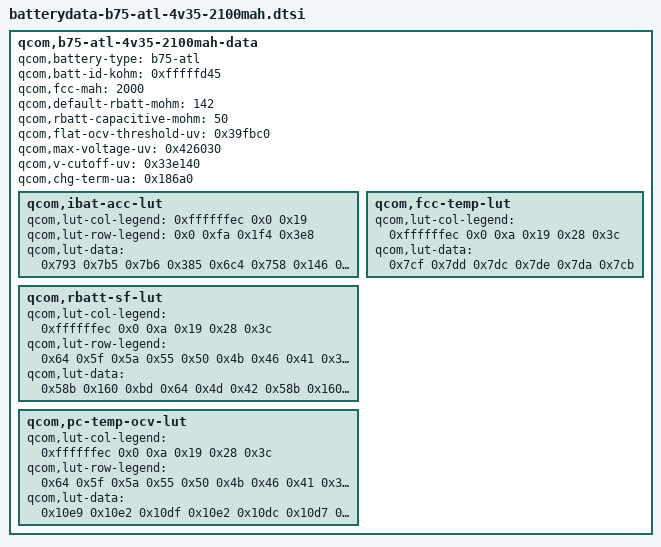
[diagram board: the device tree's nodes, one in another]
/* Copyright (c) 2020, The Linux Foundation. All rights reserved.
*  Copyright (c) 2020, the_shahnawaz_sheikh (sheikhshahnawaz41299).
*
* This program is free software; you can redistribute it and/or modify
* it under the terms of the GNU General Public License version 2 and
* only version 2 as published by the Free Software Foundation.
*
* This program is distributed in the hope that it will be useful,
* but WITHOUT ANY WARRANTY; without even the implied warranty of
* MERCHANTABILITY or FITNESS FOR A PARTICULAR PURPOSE.  See the
* GNU General Public License for more details.
*/

		qcom,b75-atl-4v35-2100mah-data {
			qcom,battery-type = "b75-atl";
			qcom,batt-id-kohm = <0xfffffd45>;
			qcom,fcc-mah = <2000>;
			qcom,default-rbatt-mohm = <142>;
			qcom,rbatt-capacitive-mohm = <50>;
			qcom,flat-ocv-threshold-uv = <0x39fbc0>;
			qcom,max-voltage-uv = <0x426030>;
			qcom,v-cutoff-uv = <0x33e140>;
			qcom,chg-term-ua = <0x186a0>;

			qcom,ibat-acc-lut {
				qcom,lut-col-legend = <0xffffffec 0x0 0x19>;
				qcom,lut-row-legend = <0x0 0xfa 0x1f4 0x3e8>;
				qcom,lut-data = <0x793 0x7b5 0x7b6 0x385 0x6c4 0x758 0x146 0x5e1 0x74a 0x6 0x563 0x746>;
			};

			qcom,rbatt-sf-lut {
				qcom,lut-col-legend = <0xffffffec 0x0 0xa 0x19 0x28 0x3c>;
				qcom,lut-row-legend = <0x64 0x5f 0x5a 0x55 0x50 0x4b 0x46 0x41 0x3c 0x37 0x32 0x2d 0x28 0x23 0x1e 0x19 0x14 0x10 0xd 0xb 0xa 0x9 0x8 0x7 0x6 0x5 0x4 0x3 0x2 0x1 0x0>;
				qcom,lut-data = <0x58b 0x160 0xbd 0x64 0x4d 0x42 0x58b 0x160 0xbd 0x64 0x4d 0x42 0x526 0x167 0xc2 0x67 0x4f 0x43 0x4d9 0x163 0xc8 0x6c 0x52 0x45 0x4ab 0x155 0xcd 0x71 0x56 0x48 0x491 0x148 0xcb 0x77 0x59 0x4b 0x487 0x141 0xc0 0x7f 0x5f 0x4e 0x488 0x13f 0xb4 0x81 0x66 0x54 0x493 0x140 0xaf 0x75 0x62 0x53 0x4af 0x145 0xaf 0x65 0x4f 0x44 0x4df 0x14b 0xb2 0x65 0x4f 0x44 0x51d 0x153 0xb6 0x68 0x52 0x47 0x56a 0x156 0xbb 0x6b 0x56 0x4a 0x5c2 0x15d 0xc1 0x6e 0x58 0x4e 0x61b 0x160 0xca 0x71 0x56 0x48 0x680 0x17b 0xd2 0x70 0x52 0x45 0x710 0x1bd 0xcd 0x70 0x52 0x45 0x8a1 0x21b 0xd3 0x6e 0x51 0x45 0xb24 0x277 0xe3 0x6b 0x4f 0x45 0xf05 0x2f9 0x10d 0x71 0x53 0x47 0x1220 0x343 0x126 0x75 0x55 0x48 0x153b 0x38d 0x140 0x7a 0x58 0x4a 0x1857 0x418 0x162 0x7f 0x5a 0x4b 0x25d8 0x597 0x1c0 0x87 0x5a 0x4c 0x3b39 0x717 0x21f 0x8f 0x5b 0x4b 0x509a 0x8b2 0x27d 0x98 0x5b 0x4b 0x8735 0x1164 0x4f9 0x9d 0x5f 0x4a 0x10e6a 0x22c8 0x94c 0xa2 0x64 0x52 0x19fab 0x4590 0x110a 0xc0 0x6d 0x5a 0x33f57 0x8b20 0x2213 0x140 0x97 0x70 0x33f57 0x8b66 0x2231 0x168 0xb5 0x98>;
			};

			qcom,fcc-temp-lut {
				qcom,lut-col-legend = <0xffffffec 0x0 0xa 0x19 0x28 0x3c>;
				qcom,lut-data = <0x7cf 0x7dd 0x7dc 0x7de 0x7da 0x7cb>;
			};

			qcom,pc-temp-ocv-lut {
				qcom,lut-col-legend = <0xffffffec 0x0 0xa 0x19 0x28 0x3c>;
				qcom,lut-row-legend = <0x64 0x5f 0x5a 0x55 0x50 0x4b 0x46 0x41 0x3c 0x37 0x32 0x2d 0x28 0x23 0x1e 0x19 0x14 0x10 0xd 0xb 0xa 0x9 0x8 0x7 0x6 0x5 0x4 0x3 0x2 0x1 0x0>;
				qcom,lut-data = <0x10e9 0x10e2 0x10df 0x10e2 0x10dc 0x10d7 0x108c 0x109d 0x109f 0x10a3 0x10a0 0x109c 0x1042 0x1061 0x1065 0x1069 0x1067 0x1064 0xfff 0x1026 0x102d 0x1032 0x1030 0x102d 0xfc2 0xfea 0xff7 0xffd 0xffc 0xffa 0xf8a 0xfb1 0xfc2 0xfcc 0xfcb 0xfca 0xf59 0xf7f 0xf8c 0xf9f 0xf9f 0xf9e 0xf2d 0xf54 0xf5c 0xf73 0xf75 0xf75 0xf06 0xf30 0xf34 0xf44 0xf49 0xf4b 0xee6 0xf10 0xf14 0xf19 0xf1b 0xf1b 0xece 0xef3 0xefa 0xefd 0xeff 0xeff 0xeba 0xeda 0xee2 0xee7 0xee9 0xeea 0xea9 0xec3 0xecf 0xed4 0xed7 0xed7 0xe9a 0xeb0 0xebf 0xec6 0xec7 0xec7 0xe89 0xe9b 0xeb2 0xeb9 0xeb7 0xeaf 0xe77 0xe8a 0xea2 0xeaa 0xea5 0xe99 0xe5f 0xe7e 0xe88 0xe94 0xe8f 0xe81 0xe44 0xe75 0xe76 0xe7d 0xe78 0xe6c 0xe2a 0xe6c 0xe6c 0xe69 0xe64 0xe5c 0xe12 0xe61 0xe64 0xe64 0xe5e 0xe53 0xe02 0xe5a 0xe61 0xe62 0xe5d 0xe52 0xdf2 0xe53 0xe5d 0xe60 0xe5b 0xe50 0xde3 0xe4a 0xe57 0xe5c 0xe5a 0xe4e 0xdcb 0xe37 0xe46 0xe51 0xe4b 0xe43 0xdad 0xe24 0xe34 0xe46 0xe3d 0xe29 0xd8f 0xe0f 0xe22 0xe3c 0xe2f 0xe0e 0xd6c 0xde4 0xdf5 0xe07 0xdfd 0xdf5 0xd39 0xdb5 0xdc2 0xdd0 0xdc3 0xda8 0xd09 0xd6a 0xd77 0xd80 0xd73 0xd5f 0xcc9 0xce9 0xcfd 0xd08 0xcf5 0xce3 0xc80 0xce4 0xce4 0xce4 0xce4 0xcb7>;
			};
		};
		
